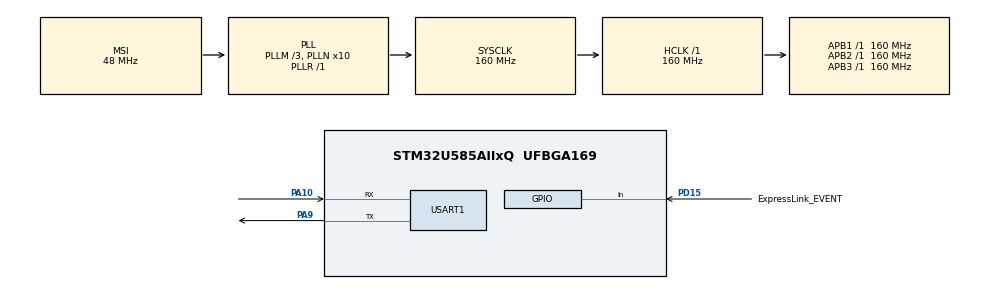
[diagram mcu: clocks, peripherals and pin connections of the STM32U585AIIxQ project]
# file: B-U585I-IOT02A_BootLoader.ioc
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CORTEX_M33_NS.userName=CORTEX_M33
Mcu.Family=STM32U5
Mcu.Name=STM32U585AIIxQ
Mcu.Package=UFBGA169
Mcu.UserConstants=CONSOLE_UART,$$_USART1_IP_HANDLE_$$
NVIC.PriorityGroup=NVIC_PRIORITYGROUP_4
NVIC.USART1_IRQn=true\:0\:0\:false\:false\:true\:true\:true\:true
PA10.Mode=Asynchronous
PA10.Signal=USART1_RX
PA9.Mode=Asynchronous
PA9.Signal=USART1_TX
PD15.GPIO_Label=ExpressLink_EVENT
PD15.Signal=GPIO_Input
PD8.Signal=USART3_TX
PD9.Signal=USART3_RX
PWR.PowerMode=PWR_SMPS_SUPPLY
ProjectManager.HeapSize=0x200
ProjectManager.StackSize=0x400
ProjectManager.TargetToolchain=STM32CubeIDE
RCC.ADCFreq_Value=16000000
RCC.AHBFreq_Value=160000000
RCC.APB1Freq_Value=160000000
RCC.APB1TimFreq_Value=160000000
RCC.APB2Freq_Value=160000000
RCC.APB2TimFreq_Value=160000000
RCC.APB3Freq_Value=160000000
RCC.CortexFreq_Value=160000000
RCC.DACCLockSelectionVirtual=RCC_DAC1CLKSOURCE_LSI
RCC.EPOD_VALUE=48000000
RCC.HCLKFreq_Value=160000000
RCC.HSE_VALUE=16000000
RCC.HSI48_VALUE=48000000
RCC.HSI_VALUE=16000000
RCC.LSE_VALUE=32768
RCC.LSIDIV_VALUE=32000
RCC.MSIClockRange=RCC_MSIRANGE_0
RCC.MSI_VALUE=48000000
RCC.PLL1R=1
RCC.PLL2FRACN=0
RCC.PLL3FRACN=0
RCC.PLLFRACN=0
RCC.PLLM=3
RCC.PLLN=10
RCC.SYSCLKFreq_VALUE=160000000
RCC.SYSCLKSource=RCC_SYSCLKSOURCE_PLLCLK
RCC.USBFreq_Value=48000000
RCC.VCOOutputFreq_Value=160000000
USART1.VirtualMode-Asynchronous=VM_ASYNC
VP_ICACHE_VS_ICACHE.Mode=DirectMappedCache
VP_LPBAMQUEUE_VS_QUEUE.Mode=QUEUEMODE
VP_LPBAM_VS_SIG1.Mode=SmartRun
VP_LPBAM_VS_SIG4.Mode=LPDMA1
VP_MEMORYMAP_VS_MEMORYMAP.Mode=CurAppReg
VP_PWR_VS_DBSignals.Mode=DisableDeadBatterySignals
VP_PWR_VS_LPOM.Mode=PowerOptimisation
VP_PWR_VS_SECSignals.Mode=Security/Privilege
VP_RTC_VS_RTC_Activate.Mode=RTC_Enabled
VP_RTC_VS_RTC_Calendar.Mode=RTC_Calendar
board=custom

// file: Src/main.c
/* USER CODE BEGIN Header */
/**
  ******************************************************************************
  * @file           : main.c
  * @brief          : Main program body
  ******************************************************************************
  * @attention
  *
  * Copyright (c) 2025 STMicroelectronics.
  * All rights reserved.
  *
  * This software is licensed under terms that can be found in the LICENSE file
  * in the root directory of this software component.
  * If no LICENSE file comes with this software, it is provided AS-IS.
  *
  ******************************************************************************
  */
/* USER CODE END Header */
#include "main.h"

/* USER CODE BEGIN Includes */
#include "rtc.h"
/* USER CODE END Includes */

RTC_HandleTypeDef hrtc;

UART_HandleTypeDef huart1;

void SystemClock_Config(void);
static void SystemPower_Config(void);
static void MX_GPIO_Init(void);
static void MX_USART1_UART_Init(void);
static void MX_ICACHE_Init(void);
static void MX_RTC_Init(void);

int main(void)
{

  /* MCU Configuration--------------------------------------------------------*/

  /* Reset of all peripherals, Initializes the Flash interface and the Systick. */
  HAL_Init();

  /* Configure the System Power */
  SystemPower_Config();

  /* Configure the system clock */
  SystemClock_Config();

  /* USER CODE BEGIN SysInit */
#if  DEBUG_LEVEL
  /* USER CODE END SysInit */

  /* Initialize all configured peripherals */
  MX_GPIO_Init();
  MX_USART1_UART_Init();
  MX_ICACHE_Init();
  MX_RTC_Init();
  /* USER CODE BEGIN 2 */
#endif

  if(check_for_hota())
  {
    PRINTF_DEBUG("\r\nNew HOTA present\r\n");
    copy_hota();
  }

  PRINTF_DEBUG("\r\nJump to main application\r\n");

#if  DEBUG_LEVEL
  HAL_Delay(5);
#endif

  Jump_To_Main_Application();

  PRINTF_ERROR("\r\nFailed to boot main application\r\n");

  /* USER CODE END 2 */

  /* Infinite loop */
  while (1)
  {

  }
}

void SystemClock_Config(void)
{
  RCC_OscInitTypeDef RCC_OscInitStruct = {0};
  RCC_ClkInitTypeDef RCC_ClkInitStruct = {0};

  /** Configure the main internal regulator output voltage
  */
  if (HAL_PWREx_ControlVoltageScaling(PWR_REGULATOR_VOLTAGE_SCALE1) != HAL_OK)
  {
    Error_Handler();
  }

  /** Initializes the CPU, AHB and APB buses clocks
  */
  RCC_OscInitStruct.OscillatorType = RCC_OSCILLATORTYPE_LSI|RCC_OSCILLATORTYPE_MSI;
  RCC_OscInitStruct.LSIState = RCC_LSI_ON;
  RCC_OscInitStruct.MSIState = RCC_MSI_ON;
  RCC_OscInitStruct.MSICalibrationValue = RCC_MSICALIBRATION_DEFAULT;
  RCC_OscInitStruct.MSIClockRange = RCC_MSIRANGE_0;
  RCC_OscInitStruct.LSIDiv = RCC_LSI_DIV1;
  RCC_OscInitStruct.PLL.PLLState = RCC_PLL_ON;
  RCC_OscInitStruct.PLL.PLLSource = RCC_PLLSOURCE_MSI;
  RCC_OscInitStruct.PLL.PLLMBOOST = RCC_PLLMBOOST_DIV4;
  RCC_OscInitStruct.PLL.PLLM = 3;
  RCC_OscInitStruct.PLL.PLLN = 10;
  RCC_OscInitStruct.PLL.PLLP = 2;
  RCC_OscInitStruct.PLL.PLLQ = 2;
  RCC_OscInitStruct.PLL.PLLR = 1;
  RCC_OscInitStruct.PLL.PLLRGE = RCC_PLLVCIRANGE_1;
  RCC_OscInitStruct.PLL.PLLFRACN = 0;
  if (HAL_RCC_OscConfig(&RCC_OscInitStruct) != HAL_OK)
  {
    Error_Handler();
  }

  /** Initializes the CPU, AHB and APB buses clocks
  */
  RCC_ClkInitStruct.ClockType = RCC_CLOCKTYPE_HCLK|RCC_CLOCKTYPE_SYSCLK
                              |RCC_CLOCKTYPE_PCLK1|RCC_CLOCKTYPE_PCLK2
                              |RCC_CLOCKTYPE_PCLK3;
  RCC_ClkInitStruct.SYSCLKSource = RCC_SYSCLKSOURCE_PLLCLK;
  RCC_ClkInitStruct.AHBCLKDivider = RCC_SYSCLK_DIV1;
  RCC_ClkInitStruct.APB1CLKDivider = RCC_HCLK_DIV1;
  RCC_ClkInitStruct.APB2CLKDivider = RCC_HCLK_DIV1;
  RCC_ClkInitStruct.APB3CLKDivider = RCC_HCLK_DIV1;

  if (HAL_RCC_ClockConfig(&RCC_ClkInitStruct, FLASH_LATENCY_5) != HAL_OK)
  {
    Error_Handler();
  }
}

/**
  * @brief Power Configuration
  * @retval None
  */
static void SystemPower_Config(void)
{

  /*
   * Disable the internal Pull-Up in Dead Battery pins of UCPD peripheral
   */
  HAL_PWREx_DisableUCPDDeadBattery();

  /*
   * Switch to SMPS regulator instead of LDO
   */
  if (HAL_PWREx_ConfigSupply(PWR_SMPS_SUPPLY) != HAL_OK)
  {
    Error_Handler();
  }
}

static void MX_ICACHE_Init(void)
{

  /** Enable instruction cache in 1-way (direct mapped cache)
  */
  if (HAL_ICACHE_ConfigAssociativityMode(ICACHE_1WAY) != HAL_OK)
  {
    Error_Handler();
  }
  if (HAL_ICACHE_Enable() != HAL_OK)
  {
    Error_Handler();
  }

}

static void MX_RTC_Init(void)
{

  /* USER CODE BEGIN RTC_Init 0 */
  // 1. Enable the Power Controller (PWR) clock
  hrtc.Instance = RTC;

  __HAL_RCC_PWR_CLK_ENABLE();

  HAL_RTC_MspInit(&hrtc);

  uint32_t magic = HAL_RTCEx_BKUPRead(&hrtc, RTC_BKP_DR0);

  if (magic != 0xCAFEFEED)
  {
    /* USER CODE END RTC_Init 0 */

    RTC_PrivilegeStateTypeDef privilegeState = { 0 };
    RTC_TimeTypeDef sTime = { 0 };
    RTC_DateTypeDef sDate = { 0 };

    /** Initialize RTC Only
     */
    hrtc.Instance = RTC;
    hrtc.Init.HourFormat = RTC_HOURFORMAT_24;
    hrtc.Init.AsynchPrediv = 127;
    hrtc.Init.SynchPrediv = 255;
    hrtc.Init.OutPut = RTC_OUTPUT_DISABLE;
    hrtc.Init.OutPutRemap = RTC_OUTPUT_REMAP_NONE;
    hrtc.Init.OutPutPolarity = RTC_OUTPUT_POLARITY_HIGH;
    hrtc.Init.OutPutType = RTC_OUTPUT_TYPE_OPENDRAIN;
    hrtc.Init.OutPutPullUp = RTC_OUTPUT_PULLUP_NONE;
    hrtc.Init.BinMode = RTC_BINARY_NONE;
    if (HAL_RTC_Init(&hrtc) != HAL_OK)
    {
      Error_Handler();
    }
    privilegeState.rtcPrivilegeFull = RTC_PRIVILEGE_FULL_NO;
    privilegeState.backupRegisterPrivZone = RTC_PRIVILEGE_BKUP_ZONE_NONE;
    privilegeState.backupRegisterStartZone2 = RTC_BKP_DR0;
    privilegeState.backupRegisterStartZone3 = RTC_BKP_DR0;
    if (HAL_RTCEx_PrivilegeModeSet(&hrtc, &privilegeState) != HAL_OK)
    {
      Error_Handler();
    }

    /** Initialize RTC and set the Time and Date
     */
    sTime.Hours = 0x0;
    sTime.Minutes = 0x0;
    sTime.Seconds = 0x0;
    sTime.DayLightSaving = RTC_DAYLIGHTSAVING_NONE;
    sTime.StoreOperation = RTC_STOREOPERATION_RESET;
    if (HAL_RTC_SetTime(&hrtc, &sTime, RTC_FORMAT_BCD) != HAL_OK)
    {
      Error_Handler();
    }
    sDate.WeekDay = RTC_WEEKDAY_MONDAY;
    sDate.Month = RTC_MONTH_JANUARY;
    sDate.Date = 0x1;
    sDate.Year = 0x0;

    if (HAL_RTC_SetDate(&hrtc, &sDate, RTC_FORMAT_BCD) != HAL_OK)
    {
      Error_Handler();
    }
    /* USER CODE BEGIN RTC_Init 2 */

    /* Enable Backup registers access*/
    HAL_PWR_EnableBkUpAccess();

    /* This allows you to check if RTC was already initialized */
    HAL_RTCEx_BKUPWrite(&hrtc, RTC_BKP_DR0, 0xCAFEFEED);

    /* Disable access to protect against accidental corruption */
    HAL_PWR_DisableBkUpAccess();
  }
  /* USER CODE END RTC_Init 2 */

}

static void MX_USART1_UART_Init(void)
{

  huart1.Instance = USART1;
  huart1.Init.BaudRate = 115200;
  huart1.Init.WordLength = UART_WORDLENGTH_8B;
  huart1.Init.StopBits = UART_STOPBITS_1;
  huart1.Init.Parity = UART_PARITY_NONE;
  huart1.Init.Mode = UART_MODE_TX_RX;
  huart1.Init.HwFlowCtl = UART_HWCONTROL_NONE;
  huart1.Init.OverSampling = UART_OVERSAMPLING_16;
  huart1.Init.OneBitSampling = UART_ONE_BIT_SAMPLE_DISABLE;
  huart1.Init.ClockPrescaler = UART_PRESCALER_DIV1;
  huart1.AdvancedInit.AdvFeatureInit = UART_ADVFEATURE_NO_INIT;
  if (HAL_UART_Init(&huart1) != HAL_OK)
  {
    Error_Handler();
  }
  if (HAL_UARTEx_SetTxFifoThreshold(&huart1, UART_TXFIFO_THRESHOLD_1_8) != HAL_OK)
  {
    Error_Handler();
  }
  if (HAL_UARTEx_SetRxFifoThreshold(&huart1, UART_RXFIFO_THRESHOLD_1_8) != HAL_OK)
  {
    Error_Handler();
  }
  if (HAL_UARTEx_DisableFifoMode(&huart1) != HAL_OK)
  {
    Error_Handler();
  }

}

static void MX_GPIO_Init(void)
{
  GPIO_InitTypeDef GPIO_InitStruct = {0};

  /* GPIO Ports Clock Enable */
  __HAL_RCC_GPIOA_CLK_ENABLE();
  __HAL_RCC_GPIOD_CLK_ENABLE();

  /*Configure GPIO pin : ExpressLink_EVENT_Pin */
  GPIO_InitStruct.Pin = ExpressLink_EVENT_Pin;
  GPIO_InitStruct.Mode = GPIO_MODE_INPUT;
  GPIO_InitStruct.Pull = GPIO_NOPULL;
  HAL_GPIO_Init(ExpressLink_EVENT_GPIO_Port, &GPIO_InitStruct);

  /*Configure GPIO pins : PD8 PD9 */
  GPIO_InitStruct.Pin = GPIO_PIN_8|GPIO_PIN_9;
  GPIO_InitStruct.Mode = GPIO_MODE_AF_PP;
  GPIO_InitStruct.Pull = GPIO_NOPULL;
  GPIO_InitStruct.Speed = GPIO_SPEED_FREQ_LOW;
  GPIO_InitStruct.Alternate = GPIO_AF7_USART3;
  HAL_GPIO_Init(GPIOD, &GPIO_InitStruct);

}

void Error_Handler(void)
{
  __disable_irq();
  while (1)
  {
  }
}
